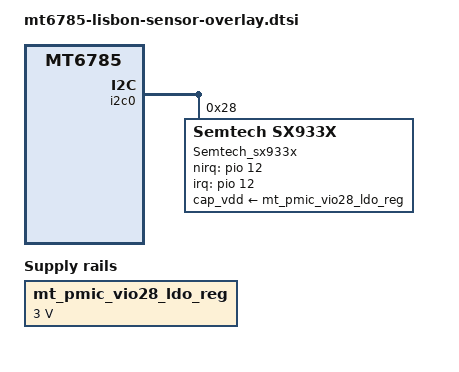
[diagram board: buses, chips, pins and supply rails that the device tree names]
&pio {
    sar_int_pin {
        sar_int_default: sar_int_default {
            /* active state */
            pinmux = <PINMUX_GPIO12__FUNC_GPIO12>;
            slew-rate = <2>;
            bias-pull-up;
        };
    };
};

&mt_pmic_vio28_ldo_reg {
        regulator-name = "vio28";
        regulator-min-microvolt = <3000000>;
        regulator-max-microvolt = <3000000>;
        regulator-enable-ramp-delay = <1920>;
};

&i2c0 {
    status = "ok";
    Semtech_sx933x@28 {
        status = "ok";
        compatible = "Semtech,sx933x";
        reg = <0x28>;
        cap_vdd-supply = <&mt_pmic_vio28_ldo_reg>;
        interrupt-parent = <&pio>;
        interrupts = <12 IRQ_TYPE_LEVEL_HIGH 12 0>;
        Semtech,nirq-gpio = <&pio 12 0x0>;
        pinctrl-names = "sar_int_default";
        pinctrl-0 = <&sar_int_default>;
        /*use PH3/4 as the reference sensor
        set it to 0xff if the ref-phases-x is not used*/
        Semtech,button-flag = <0x07>;
        Semtech,ref-phases-a = <3>;
        Semtech,ref-phases-b = <4>;
        Semtech,reg-num = <83>;
        Semtech,reg-init = <
	0x8020 0x001F0000
	0x4004 0x00000074
	0x4008 0x00000000
	0x4054 0x00000400
	0x42C0 0x08000000
	0x42C4 0x0000003F
	0x800C 0x00000000
	0x8010 0x00000000
	0x8014 0x00000000
	0x8018 0x00000000
	0x801C 0x00000031
	0x8024 0x10000A7E
	0x8028 0x3FFE825E
	0x802C 0x10000A2E
	0x8030 0x3DFF8262
	0x8034 0x10000A2E
	0x8038 0x2FFF8024
	0x803C 0x10000A2E
	0x8040 0x3FF78260
	0x8044 0x10000A2E
	0x8048 0x3FBF8024
	0x804C 0x0000088E
	0x8050 0x80001EE6
	0x8054 0x10223305
	0x8058 0x20630031
	0x805C 0x4AD25000
	0x8060 0x00000000
	0x8064 0x00450000
	0x8068 0x00000000
	0x806C 0x28002800
	0x8070 0x150000
	0x8074 0x10222D05
	0x8078 0x20630019
	0x807C 0x64C07000
	0x8080 0x00000000
	0x8084 0x400000
	0x8088 0x00000000
	0x808C 0x1F001F
	0x8090 0x00020000
	0x8094 0x10222005
	0x8098 0x20630018
	0x809C 0x64B85000
	0x80A0 0x00000000
	0x80A4 0x00270000
	0x80A8 0x00000000
	0x80AC 0x001D001D
	0x80B0 0x00020000
	0x80B4 0x1052FF00
	0x80B8 0x20630031
	0x80BC 0x54AC5300
	0x80C0 0x00000000
	0x80C4 0x00000000
	0x80C8 0x00000000
	0x80CC 0x00000000
	0x80D0 0x00000000
	0x80D4 0x1052FF00
	0x80D8 0x20630031
	0x80DC 0x54AC5300
	0x80E0 0x00000000
	0x80E4 0x00000000
	0x80E8 0x00000000
	0x80EC 0x00000000
	0x80F0 0x00000000
	0x80F4 0x10162800
	0x80F8 0x20400031
	0x80FC 0x54AC5300
	0x8100 0x00000000
	0x8104 0x00000000
	0x8108 0x00000000
	0x810C 0x00000000
	0x8110 0x00000000
	0x8124 0x400001B
	0x8128 0x400000C
	0x812C 0x00000000
	0x8130 0x00000000
	0x8134 0x00000000
	0x8138 0x00000000
	0x813C 0x00000000
	0x8140 0x00000000
	0x8144 0x00000000
	0x8148 0x00000000
	0x814C 0x00000000
	0x81A4 0x1D00010
	0x8020 0x001F001F
	0x4280 0x0000000F
        >;
    };
};
